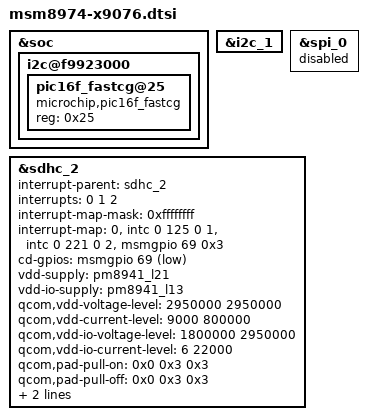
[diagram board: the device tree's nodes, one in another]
/* Copyright (c) 2012-2013, The Linux Foundation. All rights reserved.
 *
 * This program is free software; you can redistribute it and/or modify
 * it under the terms of the GNU General Public License version 2 and
 * only version 2 as published by the Free Software Foundation.
 *
 * This program is distributed in the hope that it will be useful,
 * but WITHOUT ANY WARRANTY; without even the implied warranty of
 * MERCHANTABILITY or FITNESS FOR A PARTICULAR PURPOSE.  See the
 * GNU General Public License for more details.
 */

/include/ "msm8974-oppo-common.dtsi"
/include/ "msm8974-oppo-camera.dtsi"
/include/ "msm8974-oppo-camera-sensor.dtsi"
/include/ "msm8974-oppo-input.dtsi"
/include/ "msm8974-oppo-usb.dtsi"
/include/ "msm8974-oppo-misc.dtsi"
/include/ "msm8974-oppo-pm.dtsi"
/include/ "msm8974-oppo-nfc.dtsi"
/include/ "msm8974-oppo-regulator.dtsi"
/include/ "msm8974-oppo-sound.dtsi"
/include/ "msm8974-oppo-leds.dtsi"
/include/ "msm8974-x9076-leds.dtsi"
/include/ "msm8974-x9076-mdss.dtsi"

&soc {
	i2c@f9923000 {
		pic16f_fastcg@25 {
			status = "okay";
			compatible = "microchip,pic16f_fastcg";
			reg = <0x25>;
		};
	};
};

&i2c_1 {
	status = "ok";
};

&spi_0 {
	status = "disabled";
};

&sdhc_2 {
	#address-cells = <0>;
	interrupt-parent = <&sdhc_2>;
	interrupts = <0 1 2>;
	#interrupt-cells = <1>;
	interrupt-map-mask = <0xffffffff>;
	interrupt-map = <0 &intc 0 125 0
			1 &intc 0 221 0
			2 &msmgpio 69 0x3>;
	interrupt-names = "hc_irq", "pwr_irq", "status_irq";
	cd-gpios = <&msmgpio 69 0x1>;

	vdd-supply = <&pm8941_l21>;
	vdd-io-supply = <&pm8941_l13>;

	qcom,vdd-voltage-level = <2950000 2950000>;
	qcom,vdd-current-level = <9000 800000>;

	qcom,vdd-io-voltage-level = <1800000 2950000>;
	qcom,vdd-io-current-level = <6 22000>;

	qcom,pad-pull-on = <0x0 0x3 0x3>; /* no-pull, pull-up, pull-up */
	qcom,pad-pull-off = <0x0 0x3 0x3>; /* no-pull, pull-up, pull-up */
	qcom,pad-drv-on = <0x7 0x4 0x4>; /* 16mA, 10mA, 10mA */
	qcom,pad-drv-off = <0x0 0x0 0x0>; /* 2mA, 2mA, 2mA */
	status = "ok";
};
